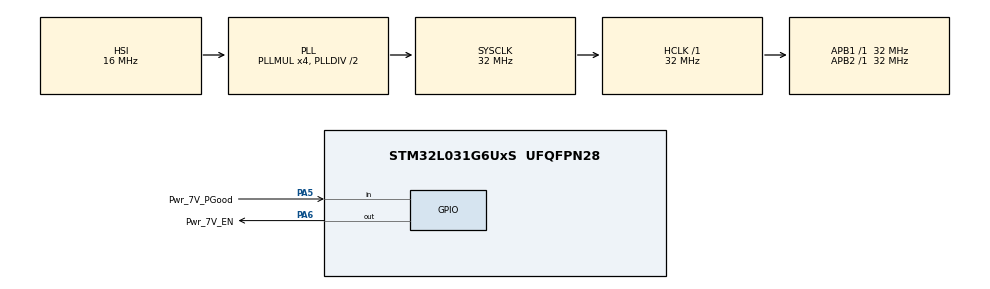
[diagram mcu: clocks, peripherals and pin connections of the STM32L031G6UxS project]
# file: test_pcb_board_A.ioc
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Mcu.Family=STM32L0
Mcu.Name=STM32L031G6UxS
Mcu.Package=UFQFPN28
PA13.Mode=Serial_Wire
PA13.Signal=SYS_SWDIO
PA14.Mode=Serial_Wire
PA14.Signal=SYS_SWCLK
PA5.GPIO_Label=Pwr_7V_PGood
PA5.Signal=GPIO_Input
PA6.GPIO_Label=Pwr_7V_EN
PA6.Signal=GPIO_Output
ProjectManager.HeapSize=0x200
ProjectManager.StackSize=0x400
ProjectManager.TargetToolchain=STM32CubeIDE
RCC.AHBFreq_Value=32000000
RCC.APB1Freq_Value=32000000
RCC.APB1TimFreq_Value=32000000
RCC.APB2Freq_Value=32000000
RCC.APB2TimFreq_Value=32000000
RCC.HCLKFreq_Value=32000000
RCC.HSE_VALUE=8000000
RCC.HSI16_VALUE=16000000
RCC.HSI_VALUE=16000000
RCC.LSE_VALUE=32768
RCC.MSI_VALUE=2097000
RCC.PLLMUL=RCC_PLLMUL_4
RCC.SYSCLKFreq_VALUE=32000000
RCC.SYSCLKSource=RCC_SYSCLKSOURCE_PLLCLK
RCC.VCOOutputFreq_Value=64000000
board=custom

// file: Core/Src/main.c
/* USER CODE BEGIN Header */
/**
  ******************************************************************************
  * @file           : main.c
  * @brief          : Main program body
  ******************************************************************************
  * @attention
  *
  * Copyright (c) 2025 STMicroelectronics.
  * All rights reserved.
  *
  * This software is licensed under terms that can be found in the LICENSE file
  * in the root directory of this software component.
  * If no LICENSE file comes with this software, it is provided AS-IS.
  *
  ******************************************************************************
  */
/* USER CODE END Header */
#include "main.h"

/* USER CODE BEGIN PV */
volatile int8_t cnt = 0;
volatile int8_t PWR_7V_PG_Value = 0, EN_PWR_7V = 0;
/* USER CODE END PV */

void SystemClock_Config(void);
static void MX_GPIO_Init(void);

int main(void)
{

  /* MCU Configuration--------------------------------------------------------*/

  /* Reset of all peripherals, Initializes the Flash interface and the Systick. */
  HAL_Init();

  /* Configure the system clock */
  SystemClock_Config();

  /* Initialize all configured peripherals */
  MX_GPIO_Init();
  /* USER CODE BEGIN 2 */
  HAL_GPIO_WritePin(Pwr_7V_EN_GPIO_Port, Pwr_7V_EN_Pin, 0);
  /* USER CODE END 2 */

  /* Infinite loop */
  /* USER CODE BEGIN WHILE */
  while (1)
  {
	  cnt ++;
	  HAL_Delay(1000);

	  if (EN_PWR_7V != 0) HAL_GPIO_WritePin(Pwr_7V_EN_GPIO_Port, Pwr_7V_EN_Pin, 1);
	  else HAL_GPIO_WritePin(Pwr_7V_EN_GPIO_Port, Pwr_7V_EN_Pin, 0);

	  PWR_7V_PG_Value = HAL_GPIO_ReadPin(Pwr_7V_PGood_GPIO_Port, Pwr_7V_PGood_Pin);

    /* USER CODE END WHILE */

  }
}

void SystemClock_Config(void)
{
  RCC_OscInitTypeDef RCC_OscInitStruct = {0};
  RCC_ClkInitTypeDef RCC_ClkInitStruct = {0};

  /** Configure the main internal regulator output voltage
  */
  __HAL_PWR_VOLTAGESCALING_CONFIG(PWR_REGULATOR_VOLTAGE_SCALE1);

  /** Initializes the RCC Oscillators according to the specified parameters
  * in the RCC_OscInitTypeDef structure.
  */
  RCC_OscInitStruct.OscillatorType = RCC_OSCILLATORTYPE_HSI;
  RCC_OscInitStruct.HSIState = RCC_HSI_ON;
  RCC_OscInitStruct.HSICalibrationValue = RCC_HSICALIBRATION_DEFAULT;
  RCC_OscInitStruct.PLL.PLLState = RCC_PLL_ON;
  RCC_OscInitStruct.PLL.PLLSource = RCC_PLLSOURCE_HSI;
  RCC_OscInitStruct.PLL.PLLMUL = RCC_PLLMUL_4;
  RCC_OscInitStruct.PLL.PLLDIV = RCC_PLLDIV_2;
  if (HAL_RCC_OscConfig(&RCC_OscInitStruct) != HAL_OK)
  {
    Error_Handler();
  }

  /** Initializes the CPU, AHB and APB buses clocks
  */
  RCC_ClkInitStruct.ClockType = RCC_CLOCKTYPE_HCLK|RCC_CLOCKTYPE_SYSCLK
                              |RCC_CLOCKTYPE_PCLK1|RCC_CLOCKTYPE_PCLK2;
  RCC_ClkInitStruct.SYSCLKSource = RCC_SYSCLKSOURCE_PLLCLK;
  RCC_ClkInitStruct.AHBCLKDivider = RCC_SYSCLK_DIV1;
  RCC_ClkInitStruct.APB1CLKDivider = RCC_HCLK_DIV1;
  RCC_ClkInitStruct.APB2CLKDivider = RCC_HCLK_DIV1;

  if (HAL_RCC_ClockConfig(&RCC_ClkInitStruct, FLASH_LATENCY_1) != HAL_OK)
  {
    Error_Handler();
  }
}

static void MX_GPIO_Init(void)
{
  GPIO_InitTypeDef GPIO_InitStruct = {0};

  /* GPIO Ports Clock Enable */
  __HAL_RCC_GPIOA_CLK_ENABLE();

  /*Configure GPIO pin Output Level */
  HAL_GPIO_WritePin(Pwr_7V_EN_GPIO_Port, Pwr_7V_EN_Pin, GPIO_PIN_RESET);

  /*Configure GPIO pin : Pwr_7V_PGood_Pin */
  GPIO_InitStruct.Pin = Pwr_7V_PGood_Pin;
  GPIO_InitStruct.Mode = GPIO_MODE_INPUT;
  GPIO_InitStruct.Pull = GPIO_NOPULL;
  HAL_GPIO_Init(Pwr_7V_PGood_GPIO_Port, &GPIO_InitStruct);

  /*Configure GPIO pin : Pwr_7V_EN_Pin */
  GPIO_InitStruct.Pin = Pwr_7V_EN_Pin;
  GPIO_InitStruct.Mode = GPIO_MODE_OUTPUT_PP;
  GPIO_InitStruct.Pull = GPIO_NOPULL;
  GPIO_InitStruct.Speed = GPIO_SPEED_FREQ_LOW;
  HAL_GPIO_Init(Pwr_7V_EN_GPIO_Port, &GPIO_InitStruct);

}

void Error_Handler(void)
{
  __disable_irq();
  while (1)
  {
  }
}
